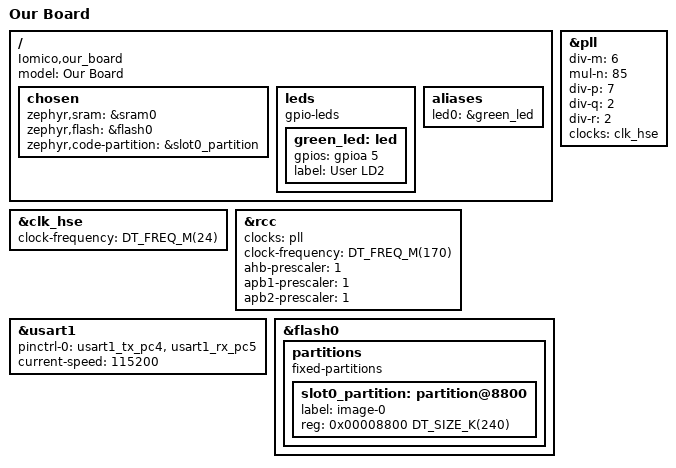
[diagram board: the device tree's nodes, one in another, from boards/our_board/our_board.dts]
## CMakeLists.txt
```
cmake_minimum_required(VERSION 3.20.0)

list(APPEND BOARD_ROOT ${CMAKE_CURRENT_SOURCE_DIR})
find_package(Zephyr REQUIRED)
project(my_zephyr_app)

target_sources(app PRIVATE src/main.c)

target_sources(app PRIVATE boards/our_board/board.c)

add_subdirectory(drivers/our_driver)
```

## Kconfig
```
menu "LED subsystem"

menuconfig LED_SUBSYSTEM 
	bool "LED_Subsystem"
	default y

	if LED_SUBSYSTEM

	choice

	prompt "LED blink sleep time"

	default BLINK_SLEEP_1000MS

	config BLINK_SLEEP_250MS
	bool "Fast (250ms)"

	config BLINK_SLEEP_1000MS
	bool "Medium (1s)"

	config BLINK_SLEEP_2000MS
	bool "Slow (2s)"
       
        endchoice

	config BLINK_SLEEP_TIME_MS
	int  
	default 250	if BLINK_SLEEP_250MS
	default 1000	if BLINK_SLEEP_1000MS
	default 2000	if BLINK_SLEEP_2000MS
	default 1000

	menu "Advanced LED settings"

	menuconfig LED_ADVANCED
	bool "LED_ADVANCED"
	default n

	if LED_ADVANCED

	config LED_BRIGHTNESS
	int "LED brightness (0-100)"
	default 100
	range 0 100

	config LED_FADE_DURATION_MS
	int "Fade duration (ms)"
	default 500
	range 0 5000

	endif

	menu "Expert settings"
	visible if LED_ADVANCED
	
	config LED_DEBUG
	bool "Enable LED debugging"

	config LED_CUSTOM_BLINK_PATTERN
	bool "Custom blink pattern"
	
	endmenu
	
	endmenu

endif # LED_SUBSYSTEM

endmenu


menu "App heartbeat"

	config APP_HEARTBEAT_PERIOD_MS
	int "App heartbeatperiod"
	default 500
	range 100 2000

endmenu

config OUR_DRIVER
    bool "our Driver"
    default y

source "Kconfig.zephyr"	

rsource "drivers/our_driver/Kconfig"
```

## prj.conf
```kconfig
CONFIG_GPIO=y
CONFIG_LOG=y
CONFIG_OUR_DRIVER=y
CONFIG_CPP=y
CONFIG_APP_HEARTBEAT_PERIOD_MS=2000
CONFIG_SHELL=y
CONFIG_SHELL_CMDS=y
CONFIG_SHELL_TAB=y
CONFIG_SHELL_TAB_AUTOCOMPLETION=y
CONFIG_SHELL_HISTORY=y
CONFIG_SHELL_LOG_BACKEND=y
```

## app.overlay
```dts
/{
	aliases{
		app-led = &green_led;
	};
};
```

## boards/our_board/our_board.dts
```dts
/*
 * Copyright (c) 2019 STMicroelectronics.
 *
 * SPDX-License-Identifier: Apache-2.0
 */

/dts-v1/;
#include <st/g4/stm32g474Xe.dtsi>
#include <st/g4/stm32g474r(b-c-e)tx-pinctrl.dtsi>
#include <zephyr/dt-bindings/input/input-event-codes.h>

/ {
	model = "Our Board";
	compatible = "Iomico,our_board";

	chosen {
		zephyr,sram = &sram0;
		zephyr,flash = &flash0;
		zephyr,code-partition = &slot0_partition;
	};

        leds: leds {
                compatible = "gpio-leds";

                green_led: led {
                        gpios = <&gpioa 5 GPIO_ACTIVE_HIGH>;
                        label = "User LD2";
                };
        };

        aliases {
                led0 = &green_led;
        };

};




&clk_hse {
	clock-frequency = <DT_FREQ_M(24)>;
	status = "okay";
};

&pll {
	div-m = <6>;
	mul-n = <85>;
	div-p = <7>;
	div-q = <2>;
	div-r = <2>;
	clocks = <&clk_hse>;
	status = "okay";
};

&rcc {
	clocks = <&pll>;
	clock-frequency = <DT_FREQ_M(170)>;
	ahb-prescaler = <1>;
	apb1-prescaler = <1>;
	apb2-prescaler = <1>;
};


&usart1 {
        pinctrl-0 = <&usart1_tx_pc4 &usart1_rx_pc5>;
        pinctrl-names = "default";
        current-speed = <115200>;
        status = "okay";
};

&flash0 {
	partitions {
		compatible = "fixed-partitions";
		#address-cells = <1>;
		#size-cells = <1>;

		slot0_partition: partition@8800 {
			label = "image-0";
			reg = <0x00008800 DT_SIZE_K(240)>;
		};
	};
};
```

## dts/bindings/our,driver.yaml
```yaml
description: Our Simple GPIO-driver
compatible: "our,driver"
include: base.yaml
```

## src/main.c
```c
#include <stdio.h>

int main(void)
{
        printf("Hello World! %s\n", CONFIG_BOARD_TARGET);

        return 0;
}
```

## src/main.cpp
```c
#include <zephyr/drivers/gpio.h>
#include <zephyr/drivers/sensor.h>
#include <zephyr/kernel.h>
#include <zephyr/logging/log.h>
#include <our_driver.h>



#define SLEEP_TIME_MS 1000

/* The devicetree node identifier for the "led0" alias. */
#define LED_NODE DT_ALIAS(led0)

static const struct gpio_dt_spec led = GPIO_DT_SPEC_GET(LED_NODE, gpios);

LOG_MODULE_REGISTER(main, LOG_LEVEL_INF);


int main(void)
{

    if (!gpio_is_ready_dt(&led)) return 0;

    if (gpio_pin_configure_dt(&led, GPIO_OUTPUT_ACTIVE) < 0) return 0;

    while (1) {

        k_msleep(SLEEP_TIME_MS);

    }

    return 0;

}
```

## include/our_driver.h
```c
#ifndef _OUR_DRIVER_INCLUDE

#define _OUR_DRIVER_INCLUDE

#include <zephyr/drivers/sensor.h>
#include <zephyr/kernel.h>

struct my_sensor_data {
    int custom_value;
};

int my_sensor_set_custom_value(const struct device *dev, int value)
{
    struct my_sensor_data *data = (struct my_sensor_data *)dev->data;
    data->custom_value = value;

    return 0;
}

#endif
```
